# Polarfire SoC register map
Vendor: Microchip; File version: 1.0
CPU: Microchip PolarFire SoC 1.0, little endian
Registers are 32-bit, read-write, reset 0x0 unless marked. A register's access mark holds for its fields unless they carry their own. Offsets are from the block's base; [hi:lo] are bit positions; {n}, {i} and the like mark numbered series.

## GEM_A_LO (part 2 of 8) — GEM_A_LO Controller
Base 0x20110000
Same registers: GEM_B_LO 0x20112000, GEM_A_HI 0x28110000, GEM_B_HI 0x28112000
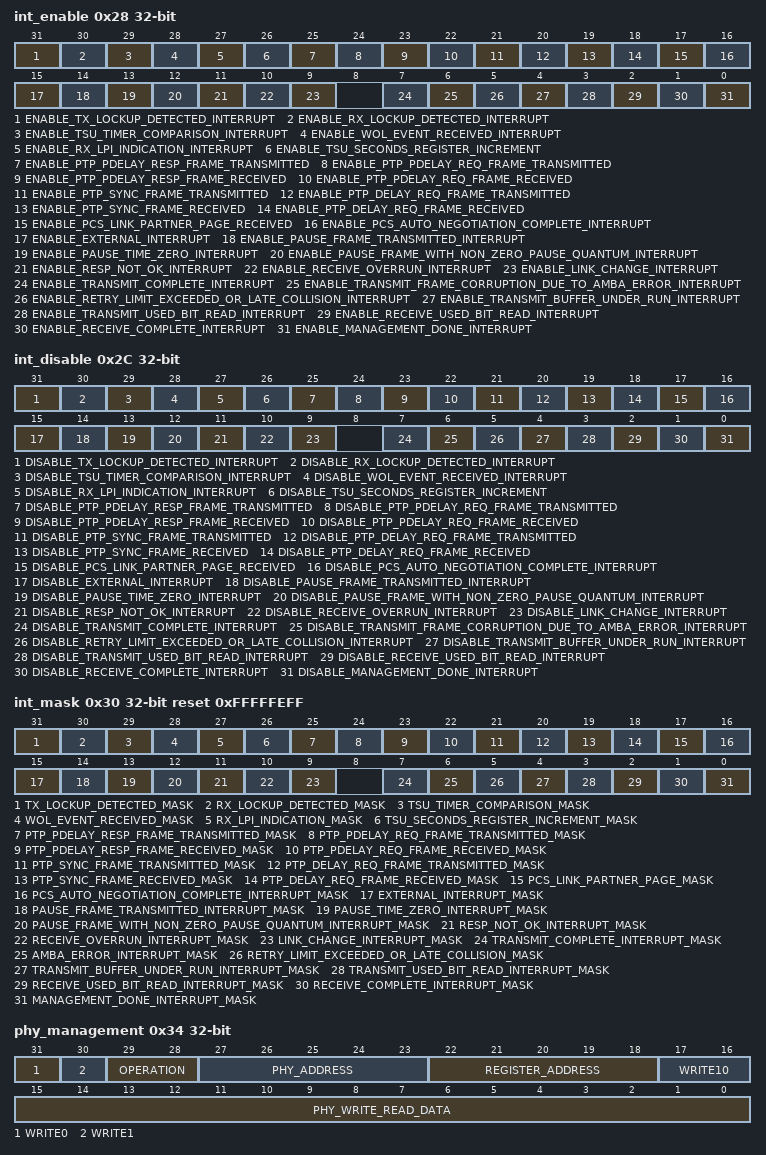
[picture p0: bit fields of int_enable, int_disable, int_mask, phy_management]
0x28 int_enable — At reset all interrupts are disabled. Writing a one to the relevant bit location enables the required interrupt. This register is write only and when read will return zero.
  [31] ENABLE_TX_LOCKUP_DETECTED_INTERRUPT — Enable TX lockup detection interrupt.
  [30] ENABLE_RX_LOCKUP_DETECTED_INTERRUPT — Enable RX lockup detection interrupt.
  [29] ENABLE_TSU_TIMER_COMPARISON_INTERRUPT
  [28] ENABLE_WOL_EVENT_RECEIVED_INTERRUPT
  [27] ENABLE_RX_LPI_INDICATION_INTERRUPT
  [26] ENABLE_TSU_SECONDS_REGISTER_INCREMENT
  [25] ENABLE_PTP_PDELAY_RESP_FRAME_TRANSMITTED
  [24] ENABLE_PTP_PDELAY_REQ_FRAME_TRANSMITTED
  [23] ENABLE_PTP_PDELAY_RESP_FRAME_RECEIVED
  [22] ENABLE_PTP_PDELAY_REQ_FRAME_RECEIVED
  [21] ENABLE_PTP_SYNC_FRAME_TRANSMITTED
  [20] ENABLE_PTP_DELAY_REQ_FRAME_TRANSMITTED
  [19] ENABLE_PTP_SYNC_FRAME_RECEIVED
  [18] ENABLE_PTP_DELAY_REQ_FRAME_RECEIVED
  [17] ENABLE_PCS_LINK_PARTNER_PAGE_RECEIVED
  [16] ENABLE_PCS_AUTO_NEGOTIATION_COMPLETE_INTERRUPT
  [15] ENABLE_EXTERNAL_INTERRUPT
  [14] ENABLE_PAUSE_FRAME_TRANSMITTED_INTERRUPT
  [13] ENABLE_PAUSE_TIME_ZERO_INTERRUPT
  [12] ENABLE_PAUSE_FRAME_WITH_NON_ZERO_PAUSE_QUANTUM_INTERRUPT
  [11] ENABLE_RESP_NOT_OK_INTERRUPT — Enable bresp/hresp not OK interrupt
  [10] ENABLE_RECEIVE_OVERRUN_INTERRUPT
  [9] ENABLE_LINK_CHANGE_INTERRUPT
  [7] ENABLE_TRANSMIT_COMPLETE_INTERRUPT
  [6] ENABLE_TRANSMIT_FRAME_CORRUPTION_DUE_TO_AMBA_ERROR_INTERRUPT — Enable transmit frame corruption due to AMBA (AHB/AXI) error interrupt
  [5] ENABLE_RETRY_LIMIT_EXCEEDED_OR_LATE_COLLISION_INTERRUPT
  [4] ENABLE_TRANSMIT_BUFFER_UNDER_RUN_INTERRUPT
  [3] ENABLE_TRANSMIT_USED_BIT_READ_INTERRUPT
  [2] ENABLE_RECEIVE_USED_BIT_READ_INTERRUPT
  [1] ENABLE_RECEIVE_COMPLETE_INTERRUPT
  [0] ENABLE_MANAGEMENT_DONE_INTERRUPT
0x2C int_disable — Writing a 1 to the relevant bit location disables that particular interrupt. This register is write only and when read will return zero.
  [31] DISABLE_TX_LOCKUP_DETECTED_INTERRUPT — Disable TX lockup detection interrupt.
  [30] DISABLE_RX_LOCKUP_DETECTED_INTERRUPT — Disable RX lockup detection interrupt.
  [29] DISABLE_TSU_TIMER_COMPARISON_INTERRUPT
  [28] DISABLE_WOL_EVENT_RECEIVED_INTERRUPT
  [27] DISABLE_RX_LPI_INDICATION_INTERRUPT
  [26] DISABLE_TSU_SECONDS_REGISTER_INCREMENT
  [25] DISABLE_PTP_PDELAY_RESP_FRAME_TRANSMITTED
  [24] DISABLE_PTP_PDELAY_REQ_FRAME_TRANSMITTED
  [23] DISABLE_PTP_PDELAY_RESP_FRAME_RECEIVED
  [22] DISABLE_PTP_PDELAY_REQ_FRAME_RECEIVED
  [21] DISABLE_PTP_SYNC_FRAME_TRANSMITTED
  [20] DISABLE_PTP_DELAY_REQ_FRAME_TRANSMITTED
  [19] DISABLE_PTP_SYNC_FRAME_RECEIVED
  [18] DISABLE_PTP_DELAY_REQ_FRAME_RECEIVED
  [17] DISABLE_PCS_LINK_PARTNER_PAGE_RECEIVED
  [16] DISABLE_PCS_AUTO_NEGOTIATION_COMPLETE_INTERRUPT
  [15] DISABLE_EXTERNAL_INTERRUPT
  [14] DISABLE_PAUSE_FRAME_TRANSMITTED_INTERRUPT
  [13] DISABLE_PAUSE_TIME_ZERO_INTERRUPT
  [12] DISABLE_PAUSE_FRAME_WITH_NON_ZERO_PAUSE_QUANTUM_INTERRUPT
  [11] DISABLE_RESP_NOT_OK_INTERRUPT — Disable bresp/hresp not OK interrupt
  [10] DISABLE_RECEIVE_OVERRUN_INTERRUPT
  [9] DISABLE_LINK_CHANGE_INTERRUPT
  [7] DISABLE_TRANSMIT_COMPLETE_INTERRUPT
  [6] DISABLE_TRANSMIT_FRAME_CORRUPTION_DUE_TO_AMBA_ERROR_INTERRUPT — Disable transmit frame corruption due to AMBA (AHB/AXI) error interrupt
  [5] DISABLE_RETRY_LIMIT_EXCEEDED_OR_LATE_COLLISION_INTERRUPT
  [4] DISABLE_TRANSMIT_BUFFER_UNDER_RUN_INTERRUPT
  [3] DISABLE_TRANSMIT_USED_BIT_READ_INTERRUPT
  [2] DISABLE_RECEIVE_USED_BIT_READ_INTERRUPT
  [1] DISABLE_RECEIVE_COMPLETE_INTERRUPT
  [0] DISABLE_MANAGEMENT_DONE_INTERRUPT
0x30 int_mask ro reset 0xFFFFFEFF — The interrupt mask register is a read only register indicating which interrupts are masked. All bits are set at reset and can be reset individually by writing to the interrupt enable register or set individually by writing to the interrupt disable register. Having separate address locations for enable and disable saves the need for performing a read modify write when updating the interrupt mask register. For test purposes there is a write-only function to this register that allows the bits in the interrupt status register to be set or cleared, regardless of the state of the mask register.
  [31] TX_LOCKUP_DETECTED_MASK — TX lockup interrupt mask.
  [30] RX_LOCKUP_DETECTED_MASK — RX lockup interrupt mask.
  [29] TSU_TIMER_COMPARISON_MASK — Enable TSU timer comparison interrupt mask.
  [28] WOL_EVENT_RECEIVED_MASK — A read of this register returns the value of the WOL event received mask., :0: Interrupt is enabled., :1: Interrupt is disabled., :A write to this register directly affects the state of the corresponding bit in the interrupt status register, causing an interrupt to be generated if a 1 is written.
  [27] RX_LPI_INDICATION_MASK — A read of this register returns the value of the RX LPI indication mask., :0: Interrupt is enabled., :1: Interrupt is disabled., :A write to this register directly affects the state of the corresponding bit in the interrupt status register, causing an interrupt to be generated if a 1 is written
  [26] TSU_SECONDS_REGISTER_INCREMENT_MASK — A read of this register returns the value of the TSU seconds register increment mask., :0: Interrupt is enabled., :1: Interrupt is disabled., :A write to this register directly affects the state of the corresponding bit in the interrupt status register, causing an interrupt to be generated if a 1 is written.
  [25] PTP_PDELAY_RESP_FRAME_TRANSMITTED_MASK — A read of this register returns the value of the PTP pdelay_resp frame transmitted mask., :0: Interrupt is enabled., :1: Interrupt is disabled., :A write to this register directly affects the state of the corresponding bit in the interrupt status register, causing an interrupt to be generated if a 1 is written.
  [24] PTP_PDELAY_REQ_FRAME_TRANSMITTED_MASK — A read of this register returns the value of the PTP pdelay_req frame transmitted mask., :0: Interrupt is enabled., :1: Interrupt is disabled., :A write to this register directly affects the state of the corresponding bit in the interrupt status register, causing an interrupt to be generated if a 1 is written.
  [23] PTP_PDELAY_RESP_FRAME_RECEIVED_MASK — A read of this register returns the value of the PTP pdelay_resp frame received mask., :0: Interrupt is enabled., :1: Interrupt is disabled., :A write to this register directly affects the state of the corresponding bit in the interrupt status register, causing an interrupt to be generated if a 1 is written.
  [22] PTP_PDELAY_REQ_FRAME_RECEIVED_MASK — A read of this register returns the value of the PTP pdelay_req frame received mask., :0: Interrupt is enabled., :1: Interrupt is disabled., :A write to this register directly affects the state of the corresponding bit in the interrupt status register, causing an interrupt to be generated if a 1 is written.
  [21] PTP_SYNC_FRAME_TRANSMITTED_MASK — A read of this register returns the value of the PTP sync frame transmitted mask., :0: Interrupt is enabled., :1: Interrupt is disabled., :A write to this register directly affects the state of the corresponding bit in the interrupt status register, causing an interrupt to be generated if a 1 is written.
  [20] PTP_DELAY_REQ_FRAME_TRANSMITTED_MASK — A read of this register returns the value of the PTP delay_req frame transmitted mask., :0: Interrupt is enabled., :1: Interrupt is disabled., :A write to this register directly affects the state of the corresponding bit in the interrupt status register, causing an interrupt to be generated if a 1 is written.
  [19] PTP_SYNC_FRAME_RECEIVED_MASK — A read of this register returns the value of the PTP sync frame received mask., :0: Interrupt is enabled., :1: Interrupt is disabled., :A write to this register directly affects the state of the corresponding bit in the interrupt status register, causing an interrupt to be generated if a 1 is written.
  [18] PTP_DELAY_REQ_FRAME_RECEIVED_MASK — A read of this register returns the value of the PTP delay_req frame received mask., :0: Interrupt is enabled., :1: Interrupt is disabled., :A write to this register directly affects the state of the corresponding bit in the interrupt status register, causing an interrupt to be generated if a 1 is written.
  [17] PCS_LINK_PARTNER_PAGE_MASK — A read of this register returns the value of the PCS link partner page mask., :0: Interrupt is enabled., :1: Interrupt is disabled., :A write to this register directly affects the state of the corresponding bit in the interrupt status register, causing an interrupt to be generated if a 1 is written.
  [16] PCS_AUTO_NEGOTIATION_COMPLETE_INTERRUPT_MASK — A read of this register returns the value of the PCS auto-negotiation complete interrupt mask., :0: Interrupt is enabled., :1: Interrupt is disabled., :A write to this register directly affects the state of the corresponding bit in the interrupt status register, causing an interrupt to be generated if a 1 is written.
  [15] EXTERNAL_INTERRUPT_MASK — External interrupt mask., :0: Interrupt is enabled., :1: Interrupt is disabled., :A write to this register directly affects the state of the corresponding bit in the interrupt status register, causing an interrupt to be generated if a 1 is written.
  [14] PAUSE_FRAME_TRANSMITTED_INTERRUPT_MASK — Pause frame transmitted interrupt mask., :0: Interrupt is enabled., :1: Interrupt is disabled., :A write to this register directly affects the state of the corresponding bit in the interrupt status register, causing an interrupt to be generated if a 1 is written.
  [13] PAUSE_TIME_ZERO_INTERRUPT_MASK — Pause time zero interrupt mask., :0: Interrupt is enabled., :1: Interrupt is disabled., :A write to this register directly affects the state of the corresponding bit in the interrupt status register, causing an interrupt to be generated if a 1 is written.
  [12] PAUSE_FRAME_WITH_NON_ZERO_PAUSE_QUANTUM_INTERRUPT_MASK — Pause frame with non-zero pause quantum interrupt mask., :0: Interrupt is enabled., :1: Interrupt is disabled. A write to this register directly affects the state of the corresponding bit in the interrupt status register, causing an interrupt to be generated if a 1 is written.
  [11] RESP_NOT_OK_INTERRUPT_MASK — bresp/hresp not OK interrupt mask., :0: Interrupt is enabled., :1: Interrupt is disabled., :A write to this register directly affects the state of the corresponding bit in the interrupt status register, causing an interrupt to be generated if a 1 is written.
  [10] RECEIVE_OVERRUN_INTERRUPT_MASK — Receive overrun interrupt mask., :0: Interrupt is enabled., :1: Interrupt is disabled., :A write to this register directly affects the state of the corresponding bit in the interrupt status register, causing an interrupt to be generated if a 1 is written.
  [9] LINK_CHANGE_INTERRUPT_MASK — A read of this register returns the value of the link change interrupt mask., :0: Interrupt is enabled., :1: Interrupt is disabled., :A write to this register directly affects the state of the corresponding bit in the interrupt status register, causing an interrupt to be generated if a 1 is written.
  [7] TRANSMIT_COMPLETE_INTERRUPT_MASK — Transmit complete interrupt mask., :0: Interrupt is enabled., :1: Interrupt is disabled., :A write to this register directly affects the state of the corresponding bit in the interrupt status register, causing an interrupt to be generated if a 1 is written.
  [6] AMBA_ERROR_INTERRUPT_MASK — Transmit frame corruption due to AMBA (AHB/AXI) error interrupt mask., :0: Interrupt is enabled., :1: Interrupt is disabled., :A write to this register directly affects the state of the corresponding bit in the interrupt status register, causing an interrupt to be generated if a 1 is written.
  [5] RETRY_LIMIT_EXCEEDED_OR_LATE_COLLISION_MASK — A read of this register returns the value of the retry limit exceeded or late collision (gigabit mode only) interrupt mask., :0: Interrupt is enabled., :1: Interrupt is disabled., :A write to this register directly affects the state of the corresponding bit in the interrupt status register, causing an interrupt to be generated if a 1 is written.
  [4] TRANSMIT_BUFFER_UNDER_RUN_INTERRUPT_MASK — Transmit buffer under run interrupt mask., :0: Interrupt is enabled., :1: Interrupt is disabled., :A write to this register directly affects the state of the corresponding bit in the interrupt status register, causing an interrupt to be generated if a 1 is written.
  [3] TRANSMIT_USED_BIT_READ_INTERRUPT_MASK — Transmit used bit read interrupt mask., :0: Interrupt is enabled., :1: Interrupt is disabled., :A write to this register directly affects the state of the corresponding bit in the interrupt status register, causing an interrupt to be generated if a 1 is written.
  [2] RECEIVE_USED_BIT_READ_INTERRUPT_MASK — Receive used bit read interrupt mask., :0: Interrupt is enabled., :1: Interrupt is disabled., :A write to this register directly affects the state of the corresponding bit in the interrupt status register, causing an interrupt to be generated if a 1 is written.
  [1] RECEIVE_COMPLETE_INTERRUPT_MASK — Receive complete interrupt mask., :0: Interrupt is enabled., :1: Interrupt is disabled., :A write to this register directly affects the state of the corresponding bit in the interrupt status register, causing an interrupt to be generated if a 1 is written.
  [0] MANAGEMENT_DONE_INTERRUPT_MASK — Management done interrupt mask., :0: Interrupt is enabled., :1: Interrupt is disabled., :A write to this register directly affects the state of the corresponding bit in the interrupt status register, causing an interrupt to be generated if a 1 is written.
0x34 phy_management — The PHY management register is implemented as a shift register. Writing to the register starts a shift operation which is signalled as complete when bit-2 is set in the network status register. It takes about 2000 pclk cycles to complete, when MDC is set for pclk divide by 32 in the network configuration register. An interrupt is generated upon completion. During this time, the MSB of the register is output on the MDIO pin and the LSB updated from the MDIO pin with each MDC cycle. This causes transmission of a PHY management frame on MDIO. See Section 22.2.4.5 of the IEEE 802.3 standard. Reading during the shift operation will return the current contents of the shift register. At the end of management operation, the bits will have shifted back to their original locations. For a read operation, the data bits will be updated with data read from the PHY. It is important to write the correct values to the register to ensure a valid PHY management frame is produced. The MDIO interface can read IEEE 802.3 clause 45 PHYs as well as clause 22 PHYs. To read clause 45 PHYs, bit 30 should be written with a 0 rather than a 1. For a description of MDC generation, see Network Configuration Register.
  [31] WRITE0 — Must be written with 0.
  [30] WRITE1 — Must be written to 1 for a valid Clause 22 frame and to 0 for a valid Clause 45 frame.
  [29:28] OPERATION — Operation. For a Clause 45 frame: 00 is an addr, 01 is a write, 10 is a post read increment, 11 is a read frame. For a Clause 22 frame: 10 is a read, 01 is a write.
  [27:23] PHY_ADDRESS
  [22:18] REGISTER_ADDRESS — Register address - specifies the register in the PHY to access.
  [17:16] WRITE10 — Must be written with 10.
  [15:0] PHY_WRITE_READ_DATA — For a write operation this is written with the data to be written to the PHY. After a read operation this contains the data read from the PHY.
0x38 pause_time ro — Received Pause Quantum Register
  [15:0] QUANTUM — Received pause quantum - stores the current value of the received pause quantum register which is decremented every 512 bit times.
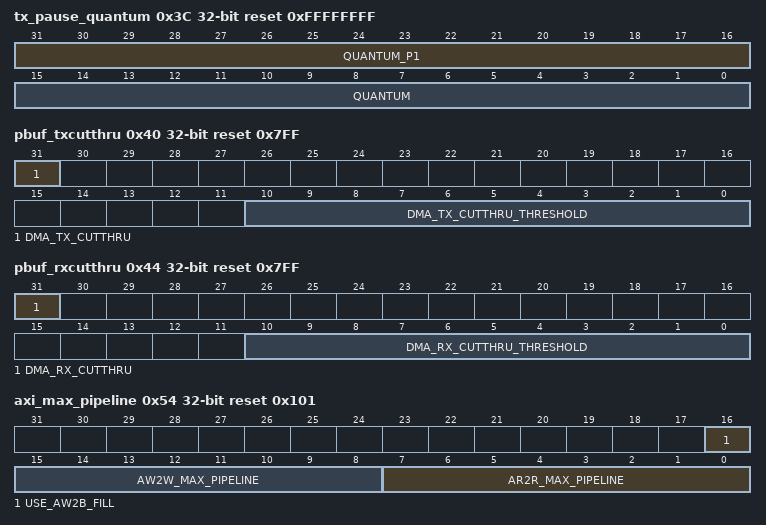
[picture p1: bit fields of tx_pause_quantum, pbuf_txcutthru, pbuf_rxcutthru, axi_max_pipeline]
0x3C tx_pause_quantum reset 0xFFFFFFFF — Transmit Pause Quantum Register
  [31:16] QUANTUM_P1 — Transmit pause quantum - written with the pause quantum value for pause frame transmission of priority 1.
  [15:0] QUANTUM — Transmit pause quantum - written with the pause quantum value for pause frame transmission.
0x40 pbuf_txcutthru reset 0x7FF — Transmit Partial Store and Forward Register. Partial store and forward is only applicable when using the DMA configured in SRAM based packet buffer mode. It is also not available when using multi buffer frames. This register contains the enable bit and watermark value for transmit cut-through operation.
  [31] DMA_TX_CUTTHRU — Enable TX partial store and forward operation
  [10:0] DMA_TX_CUTTHRU_THRESHOLD — Watermark value corresponding to number of SRAM locations. This value must be >= 0x14. The actual number of bytes for the watermark is obtained by multiplying the watermark value by the value of the gem_tx_pbuf_data define divided by 8. The reset value depends on the value of the configuration option 'gem_tx_pbuf_addr, which is defined in the verilog defs configuration file. The value chosen for the generation of the userguide was 'gem_tx_pbuf_addr = 14
0x44 pbuf_rxcutthru reset 0x7FF — Receive Partial Store and Forward Register. Partial store and forward is only applicable when using the DMA configured in SRAM based packet buffer mode. It is also not available when using multi buffer frames. This register contains the enable bit and watermark value for receive cut-through operation.
  [31] DMA_RX_CUTTHRU — Enable RX partial store and forward operation
  [10:0] DMA_RX_CUTTHRU_THRESHOLD — Watermark value corresponding to number of SRAM locations. The actual number of bytes for the watermark is obtained by multiplying the watermark value by the value of the gem_rx_pbuf_data define divided by 8. The reset value depends on the value of the configuration option 'gem_rx_pbuf_addr, which is defined in the verilog defs configuration file. The value chosen for the generation of the userguide was 'gem_rx_pbuf_addr = 11
0x48 jumbo_max_length reset 0x2800 — Maximum Jumbo Frame Size.
  [13:0] JUMBO_MAX_LENGTH — Maximum Jumbo Frame Size - resets to the gem_jumbo_max_length define value.
0x54 axi_max_pipeline reset 0x101 — Used to set the maximum amount of outstanding transactions on the AXI bus between AR / R channels and AW / W channels. Cannot be more than the depth of the configured AXI pipeline FIFO (defined in verilog defs.v)
  [16] USE_AW2B_FILL — For the write issuing capability as defined in bits 15:8 of this register, select whether the max number of transactions operates between the AW to W AXI channel or the AW to B channel. Set to 0 to operate between the AW and W channels. Set to 1 to operate between the AW and B channels.
  [15:8] AW2W_MAX_PIPELINE — Defines the maximum number of outstanding AXI write requests that can be issued by the DMA via the AW channel. This is effectively the write issuing capability.
  [7:0] AR2R_MAX_PIPELINE — Defines the maximum number of outstanding AXI read requests that can be issued by the DMA via the AR channel. This is effectively the read issuing capability.
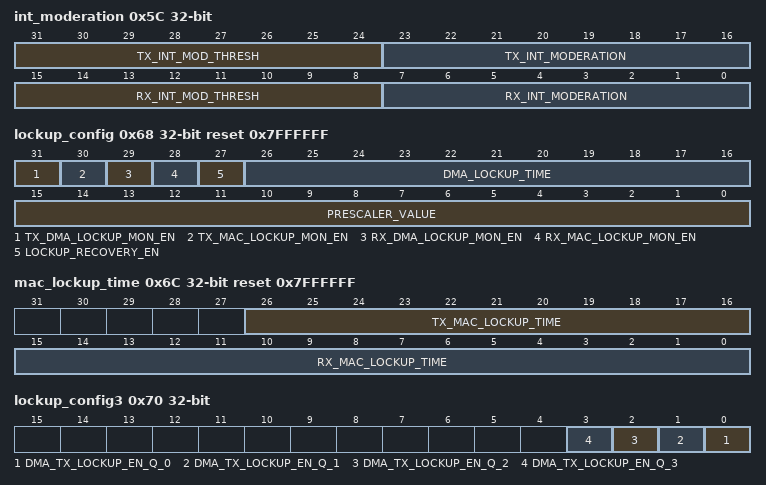
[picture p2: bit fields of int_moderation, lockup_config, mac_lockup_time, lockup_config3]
0x5C int_moderation — Used to moderate the number of transmit and receive complete interrupts issued. With interrupt moderation enabled receive and transmit interrupts are not generated immediately a frame is transmitted or received. Instead when a receive or transmit event occurs a timer is started and the interrupt is asserted after it times out. This limits the frequency with which the CPU receives interrupts. When interrupt moderation is enabled interrupt status bit one is always used for receive and bit 7 is always used for transmit even when priority queuing is enabled. With interrupt moderation 800ns periods are counted. GEM determines what constitutes an 800ns period by looking at the tbi (bit 11), gigabit bit (10) and speed (bit 0) bits in the network configuration register and counting tx_clk cycles. Bit 0 needs to be set to 1 for 100M operation., :From release 1p11 onwards a frame threshold value may also be used to moderate interrupts. If both time based and frame threshold moderation is enabled the interrupt will be asserted as soon as the first moderation method expires.
  [31:24] TX_INT_MOD_THRESH — Count of transmitted frames before bit 7 is set in the interrupt status register. A non-zero value indicates transmit interrupt moderation will be performed.
  [23:16] TX_INT_MODERATION — Count of 800ns periods before bit 7 is set in the interrupt status register after a frame is transmitted. A non-zero value indicates transmit interrupt moderation will be performed.
  [15:8] RX_INT_MOD_THRESH — Count of received frames before bit 1 is set in the interrupt status register. A non-zero value indicates receive interrupt moderation will be performed.
  [7:0] RX_INT_MODERATION — Count of 800ns periods before bit 1 is set in the interrupt status register after a frame is received. A non-zero value indicates receive interrupt moderation will be performed.
0x60 sys_wake_time — Used to pause transmission after deassertion of tx_lpi_en. Each unit in this register corresponds to 25.6ns in 2.5G mode, 64ns in gigabit mode, 320ns in 100M mode and 3200ns at 10M. After tx_lpi_en is deasserted transmission will pause for the set time.
  [15:0] SYS_WAKE_TIME — Count of 25.6ns, 64ns, 320ns or 3200ns intervals before transmission starts after deassertion of tx_lpi_en (each interval is equivalent to eight tx_clk periods and so varies with data rate).
0x68 lockup_config reset 0x7FFFFFF — The lockup detection and recovery configuration register.
  [31] TX_DMA_LOCKUP_MON_EN — Enable the TX DMA lockup detector. Enable the monitor that detects lockups in the transmit DMA.
  [30] TX_MAC_LOCKUP_MON_EN — Enable the TX MAC lockup detector. Enable the monitor that detects lockups in the MAC transmit path.
  [29] RX_DMA_LOCKUP_MON_EN — Enable the RX DMA lockup detector. Enable the monitor that detects lockups in the receive DMA.
  [28] RX_MAC_LOCKUP_MON_EN — Enable the RX MAC lockup detector. Enable the monitor that detects lockups in the MAC receive path.
  [27] LOCKUP_RECOVERY_EN — Lockup recovery. If this bit is set then the module will go into a soft reset state if a lockup is detected on the transmit or receive data paths.
  [26:16] DMA_LOCKUP_TIME — Prior to release 1p11 this field was reserved. From release 1p11 onwards this field defines the timeout value for transmit and receive DMA lockup detection defined as a multiple of the prescaler value stored in bits 15:0 of this register.
  [15:0] PRESCALER_VALUE — For release 1p10 this field defined the time (measured in units of 1024 tx_clk periods) after which the lockup detection monitors would trigger, except for the receive MAC lock up detector which had its lockup time register. From release 1p11 onwards this field defines a prescaler value which is the number of tx_clk periods used to scale the timeout registers.
0x6C mac_lockup_time reset 0x7FFFFFF — MAC lockup detection time register. For receive this register specifies the maximum time between received frames. If no valid EOP is seen at the receive FIFO interface within the timer period then a lockup is considered to have occurred in the receive MAC. For transmit the MAC lockup time is simply the time it takes for data to be seen on the MII output pins after entering on the MAC FIFO interface.
  [26:16] TX_MAC_LOCKUP_TIME — Prior to release 1p11 this field was reserved. From release 1p11 onwards this field defines the timeout value for transmit MAC lockup detection defined as a multiple of the prescaler value stored in bits 15:0 of the lockup config register.
  [15:0] RX_MAC_LOCKUP_TIME — The time after which the receive MAC lockup detection monitor will trigger. For release 1p10 this was measured in units of 1024 tx_clk periods. From release 1p11 onwards it is used in conjunction with the prescaler stored in bits 15:0 of the lockup config register.
0x70 lockup_config3 — DMA TX Lockup Enable Control Register. This register enables the lockup timer for each individual queue. If this is set to 0, the number of outstanding packets are still counted but the actual timer does not run.
  [n] DMA_TX_LOCKUP_EN_Q_{n} (n=0..3) — Enable DMA TX lockup timer for queue {n}.
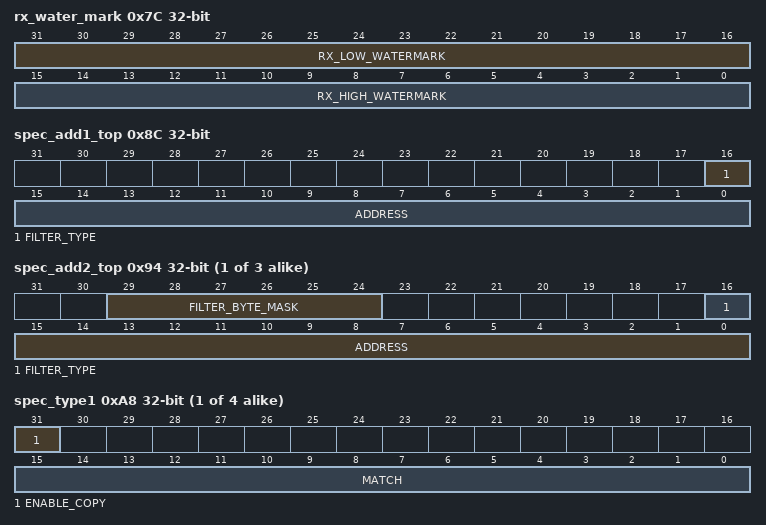
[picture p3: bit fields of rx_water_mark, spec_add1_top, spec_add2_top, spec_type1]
0x7C rx_water_mark — rx_water_mark - Receive water mark register. This register contains the high and low water-marks for automatic transmission of pause frames. The water-marks are compared against the internal signal rx_dpram_fill_lvl which is readable in the dpram_fill_dbg register; rx_dpram_fill_lvl indicates the number of words used in the receive SRAM (word length is configuration dependent and may be 4, 8 and 16 bytes). A value of zero in a field disables the corresponding functionality.
  [31:16] RX_LOW_WATERMARK — If this field is non-zero and the last pause frame transmitted was non-zero then a zero length pause frame is transmitted when the receive SRAM fill level falls below this value.
  [15:0] RX_HIGH_WATERMARK — If this field is non-zero and the receive SRAM fill level exceeds this value then a pause frame is transmitted
0x80 hash_bottom — The unicast hash enable and the multicast hash enable bits in the network configuration register enable the reception of hash matched frames. Hash Register Bottom 31:0.
  [31:0] ADDRESS — The first 32 bits of the hash address register.
0x84 hash_top — Hash Register Top 63:32
  [31:0] ADDRESS — The remaining 32 bits of the hash address register.
{0x80+8i} spec_add{i}_bottom (i=1..4) — The addresses stored in the specific address registers are deactivated at reset or when their corresponding specific address register bottom is written. They are activated when specific address register top is written.
  [31:0] ADDRESS — Octets 3 to 0 of the destination address, that is bits 31:0. Bit zero indicates whether the address is multicast or unicast and corresponds to the least significant bit of the first byte received. See the MAC Filtering Block of the user guide for more information on how to program this register.
0x8C spec_add1_top — Specific Address Top
  [16] FILTER_TYPE — This control bit selects whether this filter should be comparing the MAC source address or the MAC destination address of the received Ethernet frame. When set to zero, the filter is a destination address filter. When set to one, the filter is a source address filter.
  [15:0] ADDRESS — Specific address 1. Octets 5 and 4 of the destination/source address that is to be compared, that is bits 47:32. See MAC Filtering Block of the user guide for more information.
{0x84+8i} spec_add{i}_top (i=2..4) — Specific Address Top
  [29:24] FILTER_BYTE_MASK — When high, the associated byte of the specific address will not be compared. Bit 24 controls whether the first byte received should be compared. Bit 29 controls whether the last byte received should be compared.
  [16] FILTER_TYPE — This control bit selects whether this filter should be comparing the MAC source address or the MAC destination address of the received Ethernet frame. When set to zero, the filter is a destination address filter. When set to one, the filter is a source address filter.
  [15:0] ADDRESS — Specific address 1. The most significant bits of the destination/source address that is to be compared, that is bits 47:32. See MAC Filtering Block of the user guide for more information.
{0xA4+4i} spec_type{i} (i=1..4) — Type ID Match {i}
  [31] ENABLE_COPY — Enable copying of type ID match {i} matched frames.
  [15:0] MATCH — Type ID match {i}. For use in comparisons with received frames type ID/length field.
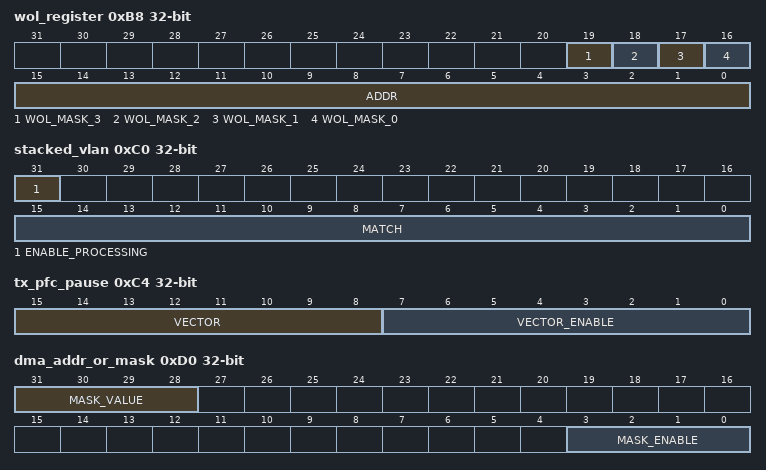
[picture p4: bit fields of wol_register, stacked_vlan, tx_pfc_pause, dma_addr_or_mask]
0xB8 wol_register — Wake on LAN Register
  [19] WOL_MASK_3 — Wake on LAN multicast hash event enable. When set multicast hash events will cause the wol output to be asserted.
  [18] WOL_MASK_2 — Wake on LAN specific address register 1 event enable. When set specific address 1 events will cause the wol output to be asserted.
  [17] WOL_MASK_1 — Wake on LAN ARP request event enable. When set ARP request events will cause the wol output to be asserted.
  [16] WOL_MASK_0 — Wake on LAN magic packet event enable. When set magic packet events will cause the wol output to be asserted.
  [15:0] ADDR — Wake on LAN ARP request IP address. Written to define the least significant 16 bits of the target IP address that is matched to generate a Wake on LAN event. A value of zero will not generate an event, even if this is matched by the received frame.
0xBC stretch_ratio — IPG stretch register
  [15:0] IPG_STRETCH — IPG Stretch. Bits 7:0 are multiplied with the previously transmitted frame length (including preamble) bits 15:8 +1 divide the frame length. If the resulting number is greater than 96 and bit 28 is set in the network configuration register then the resulting number is used for the transmit inter-packet-gap. 1 is added to bits 15:8 to prevent a divide by zero.
0xC0 stacked_vlan
  [31] ENABLE_PROCESSING — Enable stacked VLAN processing mode
  [15:0] MATCH — User defined VLAN_TYPE field. When Stacked VLAN is enabled, the first VLAN tag in a received frame will only be accepted if the VLAN type field is equal to this user defined VLAN_TYPE OR equal to the standard VLAN type (0x8100). Note that the second VLAN tag of a Stacked VLAN packet will only be matched correctly if its VLAN_TYPE field equals 0x8100.
0xC4 tx_pfc_pause — Transmit PFC Pause Register
  [15:8] VECTOR — Priority Vector Pause Size. If bit 17 of the network control register is written with a one then for each entry equal to zero in the Transmit PFC Pause Register[15:8], the PFC pause frame's pause quantum field associated with that entry will be taken from the transmit pause quantum register. For each entry equal to one in the Transmit PFC Pause Register [15:8], the pause quantum associated with that entry will be zero.
  [7:0] VECTOR_ENABLE — Priority Vector Enable. If bit 17 of the network control register is written with a one then the priority enable vector of the PFC priority based pause frame will be set equal to the value stored in this register [7:0].
0xC8 mask_add1_bottom — Specific Address Mask 1 Bottom 31:0
  [31:0] ADDRESS_MASK — Specific Address Mask. Setting a bit to one masks the corresponding bit in the specific address 1 register
0xCC mask_add1_top — Specific Address Mask 1 Top 47:32
  [15:0] ADDRESS_MASK — Specific Address Mask. Setting a bit to one masks the corresponding bit in the specific address 1 register
0xD0 dma_addr_or_mask — Receive DMA Data Buffer Address Mask - only applies to AHB operation
  [31:28] MASK_VALUE — Data Buffer Address Mask Value. Values used to force bits 31:28 of the receive data buffer AHB address to a particular value when the associated enable bits stored in this register [3:0] are set. Any changes to this register will be ignored while the DMA is currently processing a receive packet. It will only affect the next full packet to be written to external system memory.
  [3:0] MASK_ENABLE — Data Buffer Address Mask Enable. These bits are associated directly with bits[31:28].When bit 0 is set, the AHB address bit 28 used for accessing the receive data buffers will be forced to the value stored in bit 28 of this register. When bit 1 is set, the AHB address bit 29 used for accessing the receive data buffers will be forced to the value stored in bit 29 of this register. When bit 2 is set, the AHB address bit 30 used for accessing the receive data buffers will be forced to the value stored in bit 30 of this register. When bit 3 is set, the AHB address bit 31 used for accessing the receive data buffers will be forced to the value stored in bit 31 of this register. When these bits are clear, the associated value stored in bits 31:28 have no effect on the AHB address used for receive data buffer accesses. Any changes to this register will be ignored while the DMA is currently processing a receive packet. It will only affect the next full packet to be written to external memory.
0xD4 rx_ptp_unicast — PTP RX unicast IP destination address
  [31:0] ADDRESS — Unicast IP destination address. Used for detection of PTP frames on receive path.
0xD8 tx_ptp_unicast — PTP TX unicast IP destination address
  [31:0] ADDRESS — Unicast IP destination address. Used for detection of PTP frames on transmit path.
0xDC tsu_nsec_cmp — TSU timer comparison value nanoseconds
  [21:0] COMPARISON_VALUE — TSU timer comparison value (ns). Value is compared to the bits[45:24] of the TSU timer count value (upper 22 bits of nanosecond value). The output tsu_timer_cmp_val is driven high when the timer comparison values match the TSU count value. From release 1p11 onwards this comparison only occurs once the nanosecond compare register has been written and when the match occurs tsu_timer_cmp_val will only be driven high for a single tsu_clk period.
0xE0 tsu_sec_cmp — TSU timer comparison value seconds 31:0
  [31:0] COMPARISON_VALUE — TSU timer comparison value (s). Value is compared to seconds value bits [31:0] of the TSU timer count value.
0xE4 tsu_msb_sec_cmp — TSU timer comparison value seconds 47:32
  [15:0] COMPARISON_VALUE — TSU timer comparison value (s). Value is compared to the top 16 bits (most significant 16-bits [47:32] of seconds value) of the TSU timer count value.
0xE8 tsu_ptp_tx_msb_sec ro — PTP Event Frame Transmitted Seconds Register 47:32
  [15:0] TIMER_SECONDS — PTP Event Frame TX Seconds. The register is updated with the value that the 1588 timer seconds register held when the SFD of a PTP transmit primary event crosses the MII interface. The actual update occurs when the GEM recognizes the frame as a PTP sync or delay_req frame. An interrupt is issued when the register is updated.
0xEC tsu_ptp_rx_msb_sec ro — PTP Event Frame Received Seconds Register 47:32
  [15:0] TIMER_SECONDS — PTP Event Frame TX Seconds. The register is updated with the value that the 1588 timer seconds register held when the SFD of a PTP receive primary event crosses the MII interface. The actual update occurs when the GEM recognizes the frame as a PTP sync or delay_req frame. An interrupt is issued when the register is updated.
0xF0 tsu_peer_tx_msb_sec ro — PTP Peer Event Frame Transmitted Seconds Register 47:32
  [15:0] TIMER_SECONDS — PTP Peer Event Frame TX Seconds. The register is updated with the value that the 1588 timer seconds register held when the SFD of a PTP transmit peer event crosses the MII interface. The actual update occurs when the GEM recognizes the frame as a PTP pdelay_req or pdelay_resp frame. An interrupt is issued when the register is updated.
0xF4 tsu_peer_rx_msb_sec ro — PTP Peer Event Frame Received Seconds Register 47:32
  [15:0] TIMER_SECONDS — PTP Peer Event Frame RX Seconds. The register is updated with the value that the 1588 timer seconds register held when the SFD of a PTP receive peer event crosses the MII interface. The actual update occurs when the GEM recognizes the frame as a PTP pdelay_req or pdelay_resp frame. An interrupt is issued when the register is updated.
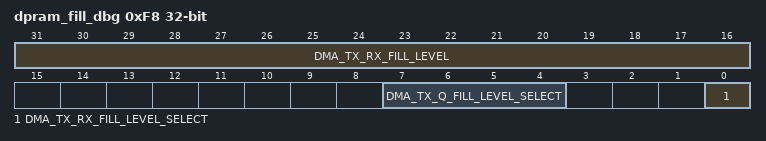
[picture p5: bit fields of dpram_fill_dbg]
0xF8 dpram_fill_dbg — The fill levels for the TX and RX packet buffer SRAMs can be read using this register, including the fill level for each queue in the TX direction. The fill level is reported as the number of word locations used. The number of bytes will depend on the SRAM data width.
  [31:16] DMA_TX_RX_FILL_LEVEL ro — Fill Level - TX or RX packet buffer fill level, selected by the tx_q_fill_level_select and tx_rx_fill_level_select registers. Read this register to determine the fill level.
  [7:4] DMA_TX_Q_FILL_LEVEL_SELECT — TX queue fill level select - select what TX queue to report fill levels for.
  [0] DMA_TX_RX_FILL_LEVEL_SELECT — TX/RX Fill Level select - report the fill level for the TX or RX packet buffer. Set 1 for transmit and 0 for receive.
